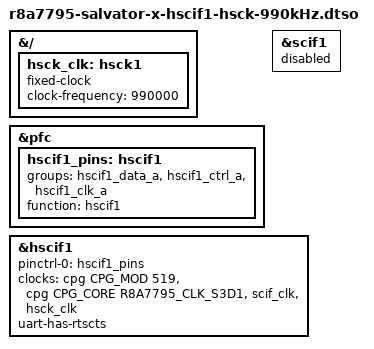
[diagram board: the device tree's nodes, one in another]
// SPDX-License-Identifier: GPL-2.0
//
// Device Tree Overlay for HSCIF1 with 990 kHz HSCK input on R-Car H3-based
// Salvator-X(S) Debug Serial 1
//
// Copyright (C) 2015 Glider bvba
//
// Notes:
//   - As these pins are shared with SCIF1, the latter is disabled first.
//
// EXIO Pinout:
//   - TXD = EXIO Connector B pin 55
//   - RXD = EXIO Connector B pin 53 [*]
//   - RTS = EXIO Connector B pin 49
//   - CTS = EXIO Connector B pin 47 [*]
//   - SCK = EXIO Connector B pin 57
//   - 3V3 = EXIO Connector B pin 41
//   - GND = EXIO Connector B pin 63
//
// [*] As these pins are driven by buffers connected to the CP2102, they can
//     be used for monitoring only, and not serve as inputs!

/dts-v1/;
/plugin/;

#include <dt-bindings/clock/r8a7795-cpg-mssr.h>

&{/} {
	hsck_clk: hsck1 {
		/* 74HC14 oscillator, R = 15K/2, C = 120J */
		compatible = "fixed-clock";
		#clock-cells = <0>;
		clock-frequency = <990000>;
		status = "okay";
	};
};

&pfc {
	hscif1_pins: hscif1 {
		groups = "hscif1_data_a", "hscif1_ctrl_a",
			 "hscif1_clk_a";
		function = "hscif1";
	};
};

&scif1 {
	status = "disabled";
};

&hscif1 {
	pinctrl-0 = <&hscif1_pins>;
	pinctrl-names = "default";

	clocks = <&cpg CPG_MOD 519>,
		 <&cpg CPG_CORE R8A7795_CLK_S3D1>,
		 <&scif_clk>, <&hsck_clk>;
	clock-names = "fck", "brg_int", "scif_clk", "hsck";

	uart-has-rtscts;
	status = "okay";
};
